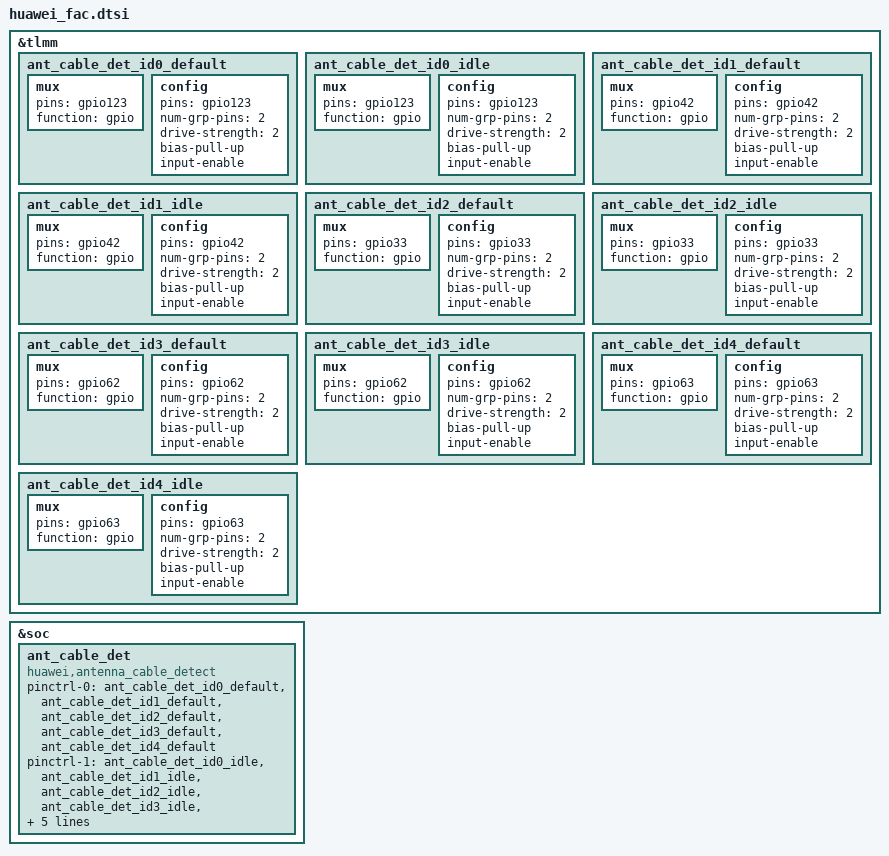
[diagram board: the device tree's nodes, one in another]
&tlmm {
	ant_cable_det_id0_default:ant_cable_det_id0_default {
			mux {
				pins = "gpio123";
				function =  "gpio";
			};
			config {
				pins = "gpio123";
				num-grp-pins = <2>;
				drive-strength = <2>;
				bias-pull-up;
				input-enable;
			};
	};
	ant_cable_det_id0_idle:ant_cable_det_id0_idle {
			mux {
				pins = "gpio123";
				function =  "gpio";
			};
			config {
				pins = "gpio123";
				num-grp-pins = <2>;
				drive-strength = <2>;
				bias-pull-up;
				input-enable;
			};
	};

	ant_cable_det_id1_default:ant_cable_det_id1_default {
			mux {
				pins = "gpio42";
				function =  "gpio";
			};
			config {
				pins = "gpio42";
				num-grp-pins = <2>;
				drive-strength = <2>;
				bias-pull-up;
				input-enable;
			};
	};
	ant_cable_det_id1_idle:ant_cable_det_id1_idle {
			mux {
				pins = "gpio42";
				function =  "gpio";
			};
			config {
				pins = "gpio42";
				num-grp-pins = <2>;
				drive-strength = <2>;
				bias-pull-up;
				input-enable;
			};
	};
	
	ant_cable_det_id2_default:ant_cable_det_id2_default {
			mux {
				pins = "gpio33";
				function =  "gpio";
			};
			config {
				pins = "gpio33";
				num-grp-pins = <2>;
				drive-strength = <2>;
				bias-pull-up;
				input-enable;
			};
	};
	ant_cable_det_id2_idle:ant_cable_det_id2_idle {
			mux {
				pins = "gpio33";
				function =  "gpio";
			};
			config {
				pins = "gpio33";
				num-grp-pins = <2>;
				drive-strength = <2>;
				bias-pull-up;
				input-enable;
			};
	};
	
	ant_cable_det_id3_default:ant_cable_det_id3_default {
			mux {
				pins = "gpio62";
				function =  "gpio";
			};
			config {
				pins = "gpio62";
				num-grp-pins = <2>;
				drive-strength = <2>;
				bias-pull-up;
				input-enable;
			};
	};
	ant_cable_det_id3_idle:ant_cable_det_id3_idle {
			mux {
				pins = "gpio62";
				function =  "gpio";
			};
			config {
				pins = "gpio62";
				num-grp-pins = <2>;
				drive-strength = <2>;
				bias-pull-up;
				input-enable;
			};
	};
	
	ant_cable_det_id4_default:ant_cable_det_id4_default {
			mux {
				pins = "gpio63";
				function =  "gpio";
			};
			config {
				pins = "gpio63";
				num-grp-pins = <2>;
				drive-strength = <2>;
				bias-pull-up;
				input-enable;
			};
	};
	ant_cable_det_id4_idle:ant_cable_det_id4_idle {
			mux {
				pins = "gpio63";
				function =  "gpio";
			};
			config {
				pins = "gpio63";
				num-grp-pins = <2>;
				drive-strength = <2>;
				bias-pull-up;
				input-enable;
			};
	};
};

&soc {
	ant_cable_det: ant_cable_det {
                compatible = "huawei,antenna_cable_detect";
                pinctrl-names = "default", "idle";
                pinctrl-0 = <&ant_cable_det_id0_default &ant_cable_det_id1_default &ant_cable_det_id2_default &ant_cable_det_id3_default &ant_cable_det_id4_default>;
                pinctrl-1 = <&ant_cable_det_id0_idle &ant_cable_det_id1_idle &ant_cable_det_id2_idle &ant_cable_det_id3_idle &ant_cable_det_id4_idle>;
                gpio_count = <5>;
                gpios = <&tlmm 123 0>,
                        <&tlmm 42 0>,
						<&tlmm 33 0>,
                        <&tlmm 62 0>,
						<&tlmm 63 0>;
                debounce-interval = <15>;
	};
};
